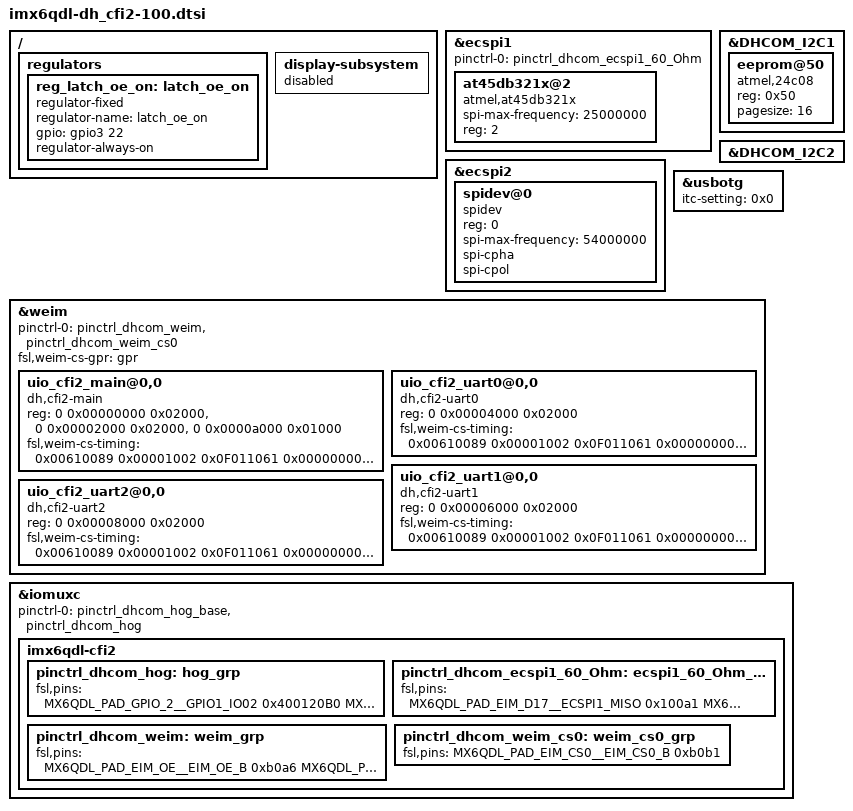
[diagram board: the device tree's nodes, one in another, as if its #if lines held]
/*
 * Copyright 2015 DH electronics GmbH
 *
 * The code contained herein is licensed under the GNU General Public
 * License. You may obtain a copy of the GNU General Public License
 * Version 2 or later at the following locations:
 *
 * http://www.opensource.org/licenses/gpl-license.html
 * http://www.gnu.org/copyleft/gpl.html
 */

/ {
	regulators {
		reg_latch_oe_on: latch_oe_on {
			compatible = "regulator-fixed";
			regulator-name = "latch_oe_on";
			#ifdef DHCOM_HW200
				gpio = <&gpio6 30 0>;				// GPIO 6.30: LATCH_OE (#190)
			#endif
			#ifdef DHCOM_HW300
				gpio = <&gpio3 22 0>;				// GPIO 3.22: LATCH_OE (#86)
			#endif
			//enable-active-high;					// Polarity of GPIO: Active low ==> Disable this property
			regulator-always-on;
		};
	};

	display-subsystem {							// Headless system
		status = "disabled";
	};
};

&ecspi1 {									// ********** SPI 1 **********
	pinctrl-0 = <&pinctrl_dhcom_ecspi1_60_Ohm>;				// DSE 60 Ohm (comment it out for default DSE 40 Ohm)
	at45db321x@2 {
		#address-cells = <1>;
		#size-cells = <1>;
		compatible = "atmel,at45db321x", "atmel,at45", "atmel,dataflash";
		spi-max-frequency = <25000000>;
		reg = <2>;							// SS2
	};
};

&ecspi2 {									// ********** SPI 2 **********
	spidev@0 {								// ==> /dev/spidev1.0
		compatible =  "spidev", "fsl,ecspi";
		reg = <0>;							// SS0
		spi-max-frequency = <54000000>;
		spi-cpha;							// Shifted clock phase (CPHA) mode
		spi-cpol;							// Inverse clock polarity (CPOL) mode
	};
};

&DHCOM_I2C1 {									// ********** I2C 1 **********
	eeprom@50 {								// Storing boot configuration
		compatible = "atmel,24c08";
		reg = <0x50>;
		pagesize = <16>;
	};
};

&DHCOM_I2C2 {									// ********** I2C 2 **********
};

&usbotg {									// USB OTG
	itc-setting = <0x0>;							// 0 micro-frames for best response of ethernet gadget
};

&weim {
	pinctrl-names = "default";
	pinctrl-0 = <&pinctrl_dhcom_weim &pinctrl_dhcom_weim_cs0>;
	#address-cells = <2>;
	#size-cells = <1>;
	/* it is necessary to setup 2x 64MB otherwise setting gpr fails */
	ranges = <0 0  0x08000000  0x04000000>,					// Chipselect A -> CFI2 FPGA
		 <1 0  0x0c000000  0x04000000>;					// Chipselect B -> CFI2 FPGA
	fsl,weim-cs-gpr = <&gpr>;
	status = "okay";

	uio_cfi2_main@0,0 {
		compatible = "dh,cfi2-main";
		reg = <0 0x00000000 0x02000>,
		      <0 0x00002000 0x02000>,
		      <0 0x0000a000 0x01000>;
		reg-names = "cfi2_general", "cfi2_misc", "cfi2_mux";
		#address-cells = <1>;
		#size-cells = <1>;
		fsl,weim-cs-timing = <0x00610089 0x00001002 0x0F011061
				      0x00000000 0x0F068A31 0x00000000>;
	};

	uio_cfi2_uart0@0,0 {
		compatible = "dh,cfi2-uart0";
		reg = <0 0x00004000 0x02000>;
		reg-names = "cfi2_uart0";
		#address-cells = <1>;
		#size-cells = <1>;
		fsl,weim-cs-timing = <0x00610089 0x00001002 0x0F011061
				      0x00000000 0x0F068A31 0x00000000>;
	};

	uio_cfi2_uart1@0,0 {
		compatible = "dh,cfi2-uart1";
		reg = <0 0x00006000 0x02000>;
		reg-names = "cfi2_uart1";
		#address-cells = <1>;
		#size-cells = <1>;
		fsl,weim-cs-timing = <0x00610089 0x00001002 0x0F011061
				      0x00000000 0x0F068A31 0x00000000>;
	};

	uio_cfi2_uart2@0,0 {
		compatible = "dh,cfi2-uart2";
		reg = <0 0x00008000 0x02000>;
		reg-names = "cfi2_uart2";
		#address-cells = <1>;
		#size-cells = <1>;
		fsl,weim-cs-timing = <0x00610089 0x00001002 0x0F011061
				      0x00000000 0x0F068A31 0x00000000>;
	};
};

&iomuxc {
	pinctrl-names = "default";
	pinctrl-0 = <&pinctrl_dhcom_hog_base &pinctrl_dhcom_hog>;

	imx6qdl-cfi2 {
		pinctrl_dhcom_hog: hog_grp {
			fsl,pins = <
				MX6QDL_PAD_GPIO_2__GPIO1_IO02       0x400120B0  // GPIO A
				MX6QDL_PAD_GPIO_4__GPIO1_IO04       0x400120B0  // GPIO B
				MX6QDL_PAD_GPIO_5__GPIO1_IO05       0x400120B0  // GPIO C
				MX6QDL_PAD_CSI0_DAT17__GPIO6_IO03   0x400120B0  // GPIO D
				MX6QDL_PAD_GPIO_19__GPIO4_IO05      0x400120B0  // GPIO E
				MX6QDL_PAD_DI0_PIN4__GPIO4_IO20     0x400120B0  // GPIO F
				MX6QDL_PAD_EIM_D27__GPIO3_IO27      0x400120B0  // GPIO G
				MX6QDL_PAD_KEY_ROW0__GPIO4_IO07     0x400120B0  // GPIO H
				MX6QDL_PAD_KEY_COL1__GPIO4_IO08     0x400120B0  // GPIO I
				MX6QDL_PAD_NANDF_CS1__GPIO6_IO14    0x120B0     // GPIO J -> Interrupt UART2 (UIO)
				MX6QDL_PAD_NANDF_CS2__GPIO6_IO15    0x400120B0  // GPIO K
				MX6QDL_PAD_KEY_ROW1__GPIO4_IO09     0x120B0     // GPIO L -> Interrupt UART0 (UIO)
				MX6QDL_PAD_SD3_DAT5__GPIO7_IO00     0x120B0     // GPIO M -> Interrupt UART1 (UIO)
				MX6QDL_PAD_SD3_DAT4__GPIO7_IO01     0x400120B0  // GPIO N
				MX6QDL_PAD_CSI0_VSYNC__GPIO5_IO21   0x400120B0  // GPIO O
				MX6QDL_PAD_GPIO_18__GPIO7_IO13      0x400120B0  // GPIO P
				MX6QDL_PAD_SD1_CMD__GPIO1_IO18      0x400120B0  // GPIO Q
				MX6QDL_PAD_SD1_DAT0__GPIO1_IO16     0x400120B0  // GPIO R
				MX6QDL_PAD_SD1_DAT1__GPIO1_IO17     0x400120B0  // GPIO S
				MX6QDL_PAD_SD1_DAT2__GPIO1_IO19     0x400120B0  // GPIO T
				MX6QDL_PAD_SD1_CLK__GPIO1_IO20      0x400120B0  // GPIO U
				MX6QDL_PAD_CSI0_PIXCLK__GPIO5_IO18  0x400120B0  // GPIO V
				MX6QDL_PAD_CSI0_MCLK__GPIO5_IO19    0x400120B0  // GPIO W
				MX6QDL_PAD_KEY_COL0__GPIO4_IO06     0x400120B0  // INT_HIGHEST_PRIORITY
			>;
		};

		pinctrl_dhcom_ecspi1_60_Ohm: ecspi1_60_Ohm_grp {		// DSE 60 Ohm
			fsl,pins = <
				MX6QDL_PAD_EIM_D17__ECSPI1_MISO     0x100a1
				MX6QDL_PAD_EIM_D18__ECSPI1_MOSI     0x100a1
				MX6QDL_PAD_EIM_D16__ECSPI1_SCLK     0x100a1
			>;
		};

		pinctrl_dhcom_weim: weim_grp {
			fsl,pins = <
				MX6QDL_PAD_EIM_OE__EIM_OE_B         0xb0a6
				MX6QDL_PAD_EIM_RW__EIM_RW           0xb0a6	// Write Enable
				MX6QDL_PAD_EIM_LBA__EIM_LBA_B       0xb060	// Latch Enable (LE)
#ifdef DHCOM_HW200
				MX6QDL_PAD_RGMII_RXC__GPIO6_IO30    0x130B0	// GPIO 6.30: LATCH_OE (#190)
#endif
#ifdef DHCOM_HW300
				MX6QDL_PAD_EIM_D22__GPIO3_IO22      0x130B0	// GPIO 3.22: LATCH_OE (#86)
#endif
				/* address/data lines */
				MX6QDL_PAD_EIM_DA15__EIM_AD15       0xb0a6
				MX6QDL_PAD_EIM_DA14__EIM_AD14       0xb0a6
				MX6QDL_PAD_EIM_DA13__EIM_AD13       0xb0a6
				MX6QDL_PAD_EIM_DA12__EIM_AD12       0xb0a6
				MX6QDL_PAD_EIM_DA11__EIM_AD11       0xb0a6
				MX6QDL_PAD_EIM_DA10__EIM_AD10       0xb0a6
				MX6QDL_PAD_EIM_DA9__EIM_AD09        0xb0a6
				MX6QDL_PAD_EIM_DA8__EIM_AD08        0xb0a6
				MX6QDL_PAD_EIM_DA7__EIM_AD07        0xb0a6
				MX6QDL_PAD_EIM_DA6__EIM_AD06        0xb0a6
				MX6QDL_PAD_EIM_DA5__EIM_AD05        0xb0a6
				MX6QDL_PAD_EIM_DA4__EIM_AD04        0xb0a6
				MX6QDL_PAD_EIM_DA3__EIM_AD03        0xb0a6
				MX6QDL_PAD_EIM_DA2__EIM_AD02        0xb0a6
				MX6QDL_PAD_EIM_DA1__EIM_AD01        0xb0a6
				MX6QDL_PAD_EIM_DA0__EIM_AD00        0xb0a6
			>;
		};

		pinctrl_dhcom_weim_cs0: weim_cs0_grp {
			fsl,pins = <
				MX6QDL_PAD_EIM_CS0__EIM_CS0_B       0xb0b1
			>;
		};
	};
};
